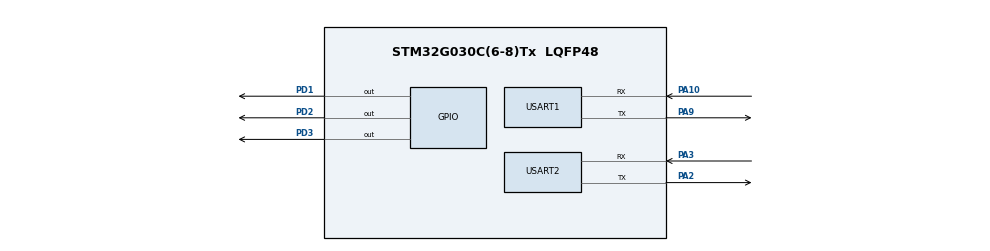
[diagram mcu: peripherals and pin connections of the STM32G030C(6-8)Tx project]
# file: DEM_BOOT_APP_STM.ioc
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Mcu.Family=STM32G0
Mcu.Name=STM32G030C(6-8)Tx
Mcu.Package=LQFP48
NVIC.USART2_IRQn=true\:0\:0\:false\:false\:true\:true\:true\:true
PA10.Mode=Asynchronous
PA10.Signal=USART1_RX
PA2.Mode=Asynchronous
PA2.Signal=USART2_TX
PA3.Mode=Asynchronous
PA3.Signal=USART2_RX
PA9.Mode=Asynchronous
PA9.Signal=USART1_TX
PD1.Signal=GPIO_Output
PD2.Signal=GPIO_Output
PD3.Signal=GPIO_Output
PF0-OSC_IN\ (PF0).Mode=HSE-External-Oscillator
PF0-OSC_IN\ (PF0).Signal=RCC_OSC_IN
PF1-OSC_OUT\ (PF1).Mode=HSE-External-Oscillator
PF1-OSC_OUT\ (PF1).Signal=RCC_OSC_OUT
ProjectManager.HeapSize=0x200
ProjectManager.StackSize=0x400
ProjectManager.TargetToolchain=STM32CubeIDE
RCC.ADCFreq_Value=64000000
RCC.AHBFreq_Value=64000000
RCC.CortexFreq_Value=64000000
RCC.EXTERNAL_CLOCK_VALUE=12288000
RCC.HCLKFreq_Value=64000000
RCC.HSE_VALUE=8000000
RCC.HSI_VALUE=16000000
RCC.LSE_VALUE=32768
RCC.SYSCLKFreq_VALUE=64000000
RCC.SYSCLKSource=RCC_SYSCLKSOURCE_PLLCLK
RCC.VCOOutputFreq_Value=128000000
USART1.VirtualMode-Asynchronous=VM_ASYNC
USART2.VirtualMode-Asynchronous=VM_ASYNC
board=custom

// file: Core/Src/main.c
/* USER CODE BEGIN Header */
/**
  ******************************************************************************
  * @file           : main.c
  * @brief          : Main program body
  ******************************************************************************
  * @attention
  *
  * Copyright (c) 2025 STMicroelectronics.
  * All rights reserved.
  *
  * This software is licensed under terms that can be found in the LICENSE file
  * in the root directory of this software component.
  * If no LICENSE file comes with this software, it is provided AS-IS.
  *
  ******************************************************************************
  */
/* USER CODE END Header */
#include "main.h"

void SystemClock_Config(void);
static void MX_GPIO_Init(void);
static void MX_USART1_UART_Init(void);
static void MX_USART2_UART_Init(void);

int main(void)
{

  /* USER CODE BEGIN 1 */
	SCB->VTOR = 0x08003000;
  /* USER CODE END 1 */

  /* MCU Configuration--------------------------------------------------------*/

  /* Reset of all peripherals, Initializes the Flash interface and the Systick. */
  LL_APB2_GRP1_EnableClock(LL_APB2_GRP1_PERIPH_SYSCFG);
  LL_APB1_GRP1_EnableClock(LL_APB1_GRP1_PERIPH_PWR);

  /* SysTick_IRQn interrupt configuration */
  NVIC_SetPriority(SysTick_IRQn, 3);

  /* Configure the system clock */
  SystemClock_Config();

  /* Initialize all configured peripherals */
  MX_GPIO_Init();
  MX_USART1_UART_Init();
  MX_USART2_UART_Init();

  /* Infinite loop */
  /* USER CODE BEGIN WHILE */
  while (1)
  {
	  // APP Modu: YEŞİL LED (PD2) Yanıp Söner
	  // Yeşil LED'in PD2 olduğunu şemadan doğruladık
	        LL_GPIO_TogglePin(GPIOD, LL_GPIO_PIN_2);

	        // Yavaş Flaş (App çalıştığını belli etsin - 50ms)
	        LL_mDelay(50);
    /* USER CODE END WHILE */

  }
}

void SystemClock_Config(void)
{
  LL_FLASH_SetLatency(LL_FLASH_LATENCY_2);
  while(LL_FLASH_GetLatency() != LL_FLASH_LATENCY_2)
  {
  }

  /* HSI configuration and activation */
  LL_RCC_HSI_Enable();
  while(LL_RCC_HSI_IsReady() != 1)
  {
  }

  /* Main PLL configuration and activation */
  LL_RCC_PLL_ConfigDomain_SYS(LL_RCC_PLLSOURCE_HSI, LL_RCC_PLLM_DIV_1, 8, LL_RCC_PLLR_DIV_2);
  LL_RCC_PLL_Enable();
  LL_RCC_PLL_EnableDomain_SYS();
  while(LL_RCC_PLL_IsReady() != 1)
  {
  }

  /* Set AHB prescaler*/
  LL_RCC_SetAHBPrescaler(LL_RCC_SYSCLK_DIV_1);

  /* Sysclk activation on the main PLL */
  LL_RCC_SetSysClkSource(LL_RCC_SYS_CLKSOURCE_PLL);
  while(LL_RCC_GetSysClkSource() != LL_RCC_SYS_CLKSOURCE_STATUS_PLL)
  {
  }

  /* Set APB1 prescaler*/
  LL_RCC_SetAPB1Prescaler(LL_RCC_APB1_DIV_1);

  LL_Init1msTick(64000000);

  /* Update CMSIS variable (which can be updated also through SystemCoreClockUpdate function) */
  LL_SetSystemCoreClock(64000000);
}

static void MX_USART1_UART_Init(void)
{

  LL_USART_InitTypeDef USART_InitStruct = {0};

  LL_GPIO_InitTypeDef GPIO_InitStruct = {0};

  LL_RCC_SetUSARTClockSource(LL_RCC_USART1_CLKSOURCE_PCLK1);

  /* Peripheral clock enable */
  LL_APB2_GRP1_EnableClock(LL_APB2_GRP1_PERIPH_USART1);

  LL_IOP_GRP1_EnableClock(LL_IOP_GRP1_PERIPH_GPIOA);
  /**USART1 GPIO Configuration
  PA9   ------> USART1_TX
  PA10   ------> USART1_RX
  */
  GPIO_InitStruct.Pin = LL_GPIO_PIN_9;
  GPIO_InitStruct.Mode = LL_GPIO_MODE_ALTERNATE;
  GPIO_InitStruct.Speed = LL_GPIO_SPEED_FREQ_LOW;
  GPIO_InitStruct.OutputType = LL_GPIO_OUTPUT_PUSHPULL;
  GPIO_InitStruct.Pull = LL_GPIO_PULL_NO;
  GPIO_InitStruct.Alternate = LL_GPIO_AF_1;
  LL_GPIO_Init(GPIOA, &GPIO_InitStruct);

  GPIO_InitStruct.Pin = LL_GPIO_PIN_10;
  GPIO_InitStruct.Mode = LL_GPIO_MODE_ALTERNATE;
  GPIO_InitStruct.Speed = LL_GPIO_SPEED_FREQ_LOW;
  GPIO_InitStruct.OutputType = LL_GPIO_OUTPUT_PUSHPULL;
  GPIO_InitStruct.Pull = LL_GPIO_PULL_NO;
  GPIO_InitStruct.Alternate = LL_GPIO_AF_1;
  LL_GPIO_Init(GPIOA, &GPIO_InitStruct);

  USART_InitStruct.PrescalerValue = LL_USART_PRESCALER_DIV1;
  USART_InitStruct.BaudRate = 115200;
  USART_InitStruct.DataWidth = LL_USART_DATAWIDTH_8B;
  USART_InitStruct.StopBits = LL_USART_STOPBITS_1;
  USART_InitStruct.Parity = LL_USART_PARITY_NONE;
  USART_InitStruct.TransferDirection = LL_USART_DIRECTION_TX_RX;
  USART_InitStruct.HardwareFlowControl = LL_USART_HWCONTROL_NONE;
  USART_InitStruct.OverSampling = LL_USART_OVERSAMPLING_16;
  LL_USART_Init(USART1, &USART_InitStruct);
  LL_USART_SetTXFIFOThreshold(USART1, LL_USART_FIFOTHRESHOLD_1_8);
  LL_USART_SetRXFIFOThreshold(USART1, LL_USART_FIFOTHRESHOLD_1_8);
  LL_USART_DisableFIFO(USART1);
  LL_USART_ConfigAsyncMode(USART1);

  LL_USART_Enable(USART1);

  /* Polling USART1 initialisation */
  while((!(LL_USART_IsActiveFlag_TEACK(USART1))) || (!(LL_USART_IsActiveFlag_REACK(USART1))))
  {
  }

}

static void MX_USART2_UART_Init(void)
{

  LL_USART_InitTypeDef USART_InitStruct = {0};

  LL_GPIO_InitTypeDef GPIO_InitStruct = {0};

  /* Peripheral clock enable */
  LL_APB1_GRP1_EnableClock(LL_APB1_GRP1_PERIPH_USART2);

  LL_IOP_GRP1_EnableClock(LL_IOP_GRP1_PERIPH_GPIOA);
  /**USART2 GPIO Configuration
  PA2   ------> USART2_TX
  PA3   ------> USART2_RX
  */
  GPIO_InitStruct.Pin = LL_GPIO_PIN_2;
  GPIO_InitStruct.Mode = LL_GPIO_MODE_ALTERNATE;
  GPIO_InitStruct.Speed = LL_GPIO_SPEED_FREQ_LOW;
  GPIO_InitStruct.OutputType = LL_GPIO_OUTPUT_PUSHPULL;
  GPIO_InitStruct.Pull = LL_GPIO_PULL_NO;
  GPIO_InitStruct.Alternate = LL_GPIO_AF_1;
  LL_GPIO_Init(GPIOA, &GPIO_InitStruct);

  GPIO_InitStruct.Pin = LL_GPIO_PIN_3;
  GPIO_InitStruct.Mode = LL_GPIO_MODE_ALTERNATE;
  GPIO_InitStruct.Speed = LL_GPIO_SPEED_FREQ_LOW;
  GPIO_InitStruct.OutputType = LL_GPIO_OUTPUT_PUSHPULL;
  GPIO_InitStruct.Pull = LL_GPIO_PULL_NO;
  GPIO_InitStruct.Alternate = LL_GPIO_AF_1;
  LL_GPIO_Init(GPIOA, &GPIO_InitStruct);

  /* USART2 interrupt Init */
  NVIC_SetPriority(USART2_IRQn, 0);
  NVIC_EnableIRQ(USART2_IRQn);

  USART_InitStruct.PrescalerValue = LL_USART_PRESCALER_DIV1;
  USART_InitStruct.BaudRate = 115200;
  USART_InitStruct.DataWidth = LL_USART_DATAWIDTH_8B;
  USART_InitStruct.StopBits = LL_USART_STOPBITS_1;
  USART_InitStruct.Parity = LL_USART_PARITY_NONE;
  USART_InitStruct.TransferDirection = LL_USART_DIRECTION_TX_RX;
  USART_InitStruct.HardwareFlowControl = LL_USART_HWCONTROL_NONE;
  USART_InitStruct.OverSampling = LL_USART_OVERSAMPLING_16;
  LL_USART_Init(USART2, &USART_InitStruct);
  LL_USART_ConfigAsyncMode(USART2);

  LL_USART_Enable(USART2);

  /* Polling USART2 initialisation */
  while((!(LL_USART_IsActiveFlag_TEACK(USART2))) || (!(LL_USART_IsActiveFlag_REACK(USART2))))
  {
  }

}

static void MX_GPIO_Init(void)
{
  LL_GPIO_InitTypeDef GPIO_InitStruct = {0};

  /* GPIO Ports Clock Enable */
  LL_IOP_GRP1_EnableClock(LL_IOP_GRP1_PERIPH_GPIOF);
  LL_IOP_GRP1_EnableClock(LL_IOP_GRP1_PERIPH_GPIOA);
  LL_IOP_GRP1_EnableClock(LL_IOP_GRP1_PERIPH_GPIOD);

  /**/
  LL_GPIO_ResetOutputPin(GPIOD, LL_GPIO_PIN_1);

  /**/
  LL_GPIO_ResetOutputPin(GPIOD, LL_GPIO_PIN_2);

  /**/
  LL_GPIO_ResetOutputPin(GPIOD, LL_GPIO_PIN_3);

  /**/
  GPIO_InitStruct.Pin = LL_GPIO_PIN_1;
  GPIO_InitStruct.Mode = LL_GPIO_MODE_OUTPUT;
  GPIO_InitStruct.Speed = LL_GPIO_SPEED_FREQ_LOW;
  GPIO_InitStruct.OutputType = LL_GPIO_OUTPUT_PUSHPULL;
  GPIO_InitStruct.Pull = LL_GPIO_PULL_NO;
  LL_GPIO_Init(GPIOD, &GPIO_InitStruct);

  /**/
  GPIO_InitStruct.Pin = LL_GPIO_PIN_2;
  GPIO_InitStruct.Mode = LL_GPIO_MODE_OUTPUT;
  GPIO_InitStruct.Speed = LL_GPIO_SPEED_FREQ_LOW;
  GPIO_InitStruct.OutputType = LL_GPIO_OUTPUT_PUSHPULL;
  GPIO_InitStruct.Pull = LL_GPIO_PULL_NO;
  LL_GPIO_Init(GPIOD, &GPIO_InitStruct);

  /**/
  GPIO_InitStruct.Pin = LL_GPIO_PIN_3;
  GPIO_InitStruct.Mode = LL_GPIO_MODE_OUTPUT;
  GPIO_InitStruct.Speed = LL_GPIO_SPEED_FREQ_LOW;
  GPIO_InitStruct.OutputType = LL_GPIO_OUTPUT_PUSHPULL;
  GPIO_InitStruct.Pull = LL_GPIO_PULL_NO;
  LL_GPIO_Init(GPIOD, &GPIO_InitStruct);

}

void Error_Handler(void)
{
  __disable_irq();
  while (1)
  {
  }
}
